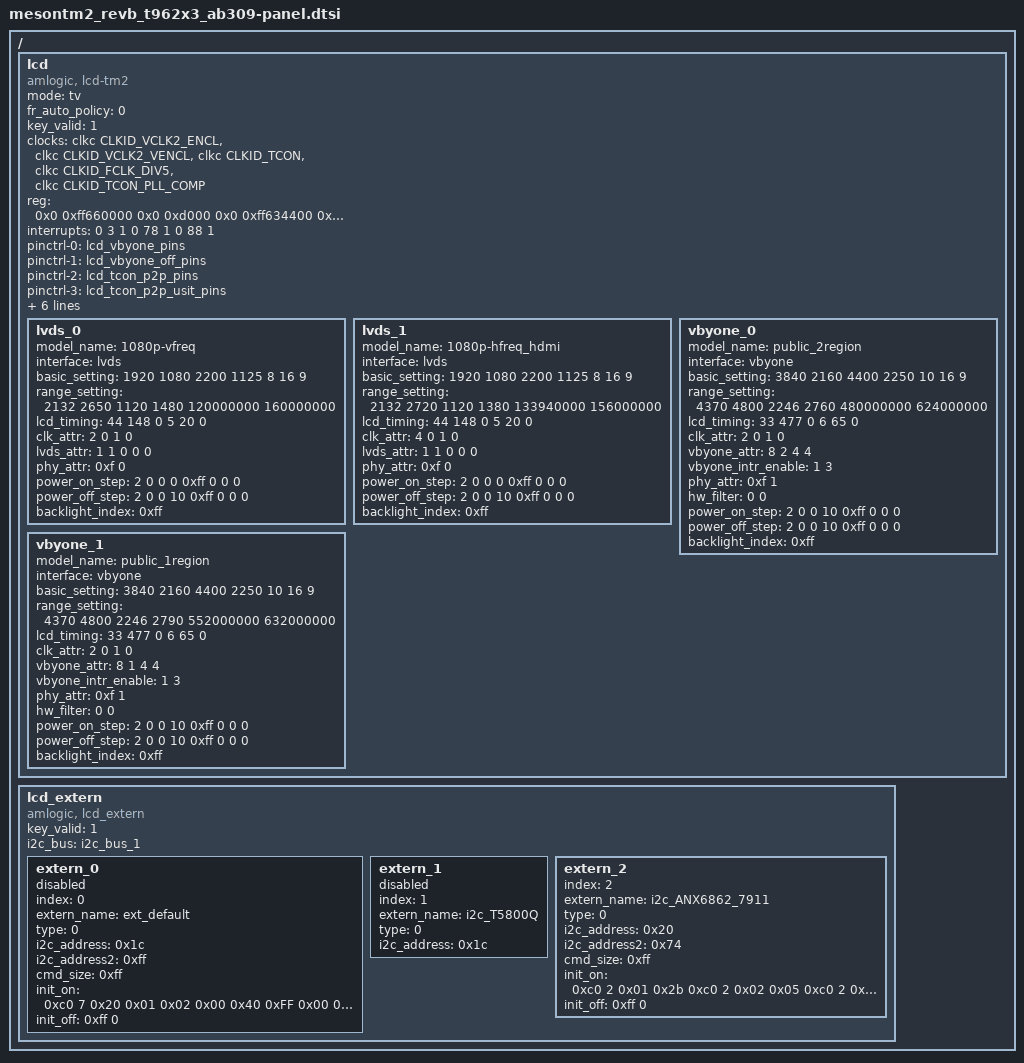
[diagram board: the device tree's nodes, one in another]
// SPDX-License-Identifier: (GPL-2.0+ OR MIT)
/*
 * arch/arm64/boot/dts/amlogic/mesontm2_revb_t962x3_ab309-panel.dtsi
 *
 * Copyright (C) 2019 Amlogic, Inc. All rights reserved.
 *
 */

/ {
	lcd {
		compatible = "amlogic, lcd-tm2";
		status = "okay";
		mode = "tv";
		fr_auto_policy = <0>; /* 0=disable, 1=60/50hz, 2=60/50/48hz */
		key_valid = <1>;
		clocks = <&clkc CLKID_VCLK2_ENCL
			&clkc CLKID_VCLK2_VENCL
			&clkc CLKID_TCON
			&clkc CLKID_FCLK_DIV5
			&clkc CLKID_TCON_PLL_COMP>;
		clock-names = "encl_top_gate",
			"encl_int_gate",
			"tcon_gate",
			"fclk_div5",
			"clk_tcon";
		reg = <0x0 0xff660000 0x0 0xd000
			0x0 0xff634400 0x0 0x300>;
		interrupts = <0 3 1
			0 78 1
			0 88 1>;
		interrupt-names = "vsync","vbyone","tcon";
		pinctrl-names = "vbyone","vbyone_off",
				"tcon_p2p","tcon_p2p_usit","tcon_p2p_off",
				"tcon_mlvds","tcon_mlvds_off";
		pinctrl-0 = <&lcd_vbyone_pins>;
		pinctrl-1 = <&lcd_vbyone_off_pins>;
		pinctrl-2 = <&lcd_tcon_p2p_pins>;
		pinctrl-3 = <&lcd_tcon_p2p_usit_pins>;
		pinctrl-4 = <&lcd_tcon_p2p_off_pins>;
		pinctrl-5 = <&lcd_tcon_mlvds_pins>;
		pinctrl-6 = <&lcd_tcon_mlvds_off_pins>;
		pinctrl_version = <2>; /* for uboot */

		/* power type:(0=cpu_gpio, 2=signal, 3=extern, 0xff=ending) */
		/* power index:(gpios_index, or extern_index, 0xff=invalid) */
		/* power value:(0=output low, 1=output high, 2=input) */
		/* power delay:(unit in ms) */

		config_check_glb = <1>;
		display_timing_req_min = <1  /*alert_level: 0:disable, 1:warning, 2:fatal error*/
			45   /*hsw+hbp*/
			0    /*hfp, 0 for no need*/
			20   /*vsw+vbp*/
			15>; /*vfp*/

		lvds_0{
			model_name = "1080p-vfreq";
			interface = "lvds"; /*lcd_interface(lvds, vbyone)*/
			basic_setting = <
				1920 1080 /*h_active, v_active*/
				2200 1125 /*h_period, v_period*/
				8      /*lcd_bits */
				16 9>; /*screen_widht, screen_height*/
			range_setting = <
				2132 2650  /*h_period_min,max*/
				1120 1480  /*v_period_min,max*/
				120000000 160000000>; /*pclk_min,max*/
			lcd_timing = <
				44 148 0  /*hs_width, hs_bp, hs_pol*/
				5  20 0>; /*vs_width, vs_bp, vs_pol*/
			clk_attr = <
				2 /*fr_adj_type: 0=clk, 1=htotal, 2=vtotal, 3=auto, 4=hdmi */
				0 /*clk_ss: [0:7]:level, [8:11]:freq, [12:15]: mode*/
				1 /*clk_auto_generate*/
				0>; /*pixel_clk(unit in Hz)*/
			lvds_attr = <
				1  /*lvds_repack*/
				1  /*dual_port*/
				0  /*pn_swap*/
				0  /*port_swap*/
				0>; /*lane_reverse*/
			phy_attr=<0xf 0>; /*vswing_level, preem_level*/

			/* power step: type, index, value, delay(ms) */
			power_on_step = <
				2 0 0 0   /*signal enable*/
				0xff 0 0 0>; /*ending*/
			power_off_step = <
				2 0 0 10  /*signal disable*/
				0xff 0 0 0>; /*ending*/
			backlight_index = <0xff>;
		};
		lvds_1{
			model_name = "1080p-hfreq_hdmi";
			interface = "lvds"; /*lcd_interface(lvds, vbyone)*/
			basic_setting = <
				1920 1080 /*h_active, v_active*/
				2200 1125 /*h_period, v_period*/
				8      /*lcd_bits*/
				16 9>; /*screen_widht, screen_height*/
			range_setting = <
				2132 2720 /*h_period min, max*/
				1120 1380 /*v_period min, max*/
				133940000 156000000>; /*pclk_min, max*/
			lcd_timing = <
				44 148 0   /*hs_width, hs_bp, hs_pol*/
				5  20  0>; /*vs_width, vs_bp, vs_pol*/
			clk_attr = <
				4 /*fr_adj_type: 0=clk, 1=htotal, 2=vtotal, 3=auto, 4=hdmi */
				0 /*clk_ss: [0:7]:level, [8:11]:freq, [12:15]: mode */
				1 /*clk_auto_generate*/
				0>; /*pixel_clk(unit in Hz)*/
			lvds_attr = <
				1 /*lvds_repack*/
				1 /*dual_port*/
				0 /*pn_swap*/
				0 /*port_swap*/
				0>; /*lane_reverse*/
			phy_attr=<0xf 0>; /*vswing_level, preem_level*/

			/* power step: type, index, value, delay(ms) */
			power_on_step = <
				2 0 0 0   /*signal enable*/
				0xff 0 0 0>; /*ending*/
			power_off_step = <
				2 0 0 10  /*signal disable*/
				0xff 0 0 0>; /*ending*/
			backlight_index = <0xff>;
		};
		vbyone_0{
			model_name = "public_2region";
			interface = "vbyone"; /*lcd_interface(lvds, vbyone)*/
			basic_setting = <
				3840 2160 /*h_active, v_active*/
				4400 2250 /*h_period, v_period*/
				10     /*lcd_bits */
				16 9>; /*screen_widht, screen_height*/
			range_setting = <
				4370 4800 /*h_period_min, max*/
				2246 2760 /*v_period_min, max*/
				480000000 624000000>; /*pclk_min, max*/
			lcd_timing = <
				33 477 0  /*hs_width, hs_bp, hs_pol*/
				6  65 0>; /*vs_width, vs_bp, vs_pol*/
			clk_attr = <
				2 /*fr_adj_type: 0=clk, 1=htotal, 2=vtotal, 3=auto, 4=hdmi */
				0 /*clk_ss: [0:7]:level, [8:11]:freq, [12:15]: mode*/
				1 /*clk_auto_generate*/
				0>; /*pixel_clk(unit in Hz)*/
			vbyone_attr = <
				8 /*lane_count*/
				2 /*region_num*/
				4 /*byte_mode*/
				4>; /*color_fmt*/
			vbyone_intr_enable = <
				1 /*vbyone_intr_enable */
				3>; /*vbyone_vsync_intr_enable*/
			phy_attr=<0xf 1>; /* vswing_level, preem_level */
			hw_filter=<0 0>;  /* filter_time, filter_cnt*/

			/* power step: type, index, value, delay(ms) */
			power_on_step = <
				2 0 0 10  /*signal enable*/
				0xff 0 0 0>; /*ending*/
			power_off_step = <
				2 0 0 10 /*signal disable*/
				0xff 0 0 0>; /*ending*/
			backlight_index = <0xff>;
		};
		vbyone_1{
			model_name = "public_1region";
			interface = "vbyone"; /*lcd_interface(lvds, vbyone)*/
			basic_setting = <
				3840 2160 /*h_active, v_active*/
				4400 2250 /*h_period, v_period*/
				10     /*lcd_bits*/
				16 9>; /*screen_widht, screen_height*/
			range_setting = <
				4370 4800 /*h_period_min, max*/
				2246 2790 /*v_period_min, max*/
				552000000 632000000>; /*pclk_min,max*/
			lcd_timing = <
				33 477 0   /*hs_width, hs_bp, hs_pol*/
				6  65  0>; /*vs_width, vs_bp, vs_pol*/
			clk_attr = <
				2 /*fr_adj_type: 0=clk, 1=htotal, 2=vtotal, 3=auto, 4=hdmi */
				0 /*clk_ss: [0:7]:level, [8:11]:freq, [12:15]: mode*/
				1 /*clk_auto_generate*/
				0>; /*pixel_clk(unit in Hz)*/
			vbyone_attr = <
				8 /*lane_count*/
				1 /*region_num*/
				4 /*byte_mode*/
				4>; /*color_fmt*/
			vbyone_intr_enable = <
				1   /*vbyone_intr_enable*/
				3>; /*vbyone_vsync_intr_enable*/
			phy_attr=<0xf 1>; /* vswing_level, preem_level */
			hw_filter=<0 0>;  /* filter_time, filter_cnt*/

			/* power step: type, index, value, delay(ms) */
			power_on_step = <
				2 0 0 10 /*signal enable*/
				0xff 0 0 0>; /*ending*/
			power_off_step = <
				2 0 0 10  /*signal disable*/
				0xff 0 0 0>; /*ending*/
			backlight_index = <0xff>;
		};
	};

	lcd_extern{
		compatible = "amlogic, lcd_extern";
		status = "okay";
		key_valid = <1>;
		i2c_bus = "i2c_bus_1";

		extern_0{
			index = <0>;
			extern_name = "ext_default";
			status = "disabled";
			type = <0>; /*0=i2c, 1=spi, 2=mipi*/
			i2c_address = <0x1c>; /*7bit i2c_addr*/
			i2c_address2 = <0xff>;
			cmd_size = <0xff>; /*dynamic cmd_size*/

			/* init on/off:
			 *  fixed cmd_size: (type, value...);
			 *                  cmd_size include all data.
			 *  dynamic cmd_size: (type, cmd_size, value...);
			 *                    cmd_size include value.
			 */
			/* type: 0x00=cmd with delay(bit[3:0]=1 for address2),
			 *       0xc0=cmd(bit[3:0]=1 for address2),
			 *       0xf0=gpio,
			 *       0xfd=delay,
			 *       0xff=ending
			 */
			/* value: i2c or spi cmd, or gpio index & level */
			/* delay: unit ms */
			init_on = <
				0xc0 7 0x20 0x01 0x02 0x00 0x40 0xFF 0x00
				0xc0 7 0x80 0x02 0x00 0x40 0x62 0x51 0x73
				0xc0 7 0x61 0x06 0x00 0x00 0x00 0x00 0x00
				0xc0 7 0xC1 0x05 0x0F 0x00 0x08 0x70 0x00
				0xc0 7 0x13 0x01 0x00 0x00 0x00 0x00 0x00
				0xc0 7 0x3D 0x02 0x01 0x00 0x00 0x00 0x00
				0xc0 7 0xED 0x0D 0x01 0x00 0x00 0x00 0x00
				0xc0 7 0x23 0x02 0x00 0x00 0x00 0x00 0x00
				0xfd 1 10 /* delay 10ms */
				0xff 0>; /*ending*/
			init_off = <0xff 0>; /*ending*/
		};
		extern_1{
			index = <1>;
			extern_name = "i2c_T5800Q";
			status = "disabled";
			type = <0>; /* 0=i2c, 1=spi, 2=mipi */
			i2c_address = <0x1c>; /* 7bit i2c address */
		};
		extern_2{
			index = <2>;
			extern_name = "i2c_ANX6862_7911";
			status = "okay";
			type = <0>; /* 0=i2c, 1=spi, 2=mipi */
			i2c_address = <0x20>; /* 7bit i2c address */
			i2c_address2 = <0x74>; /* 7bit i2c address */
			cmd_size = <0xff>;

			init_on = <
				0xc0 2 0x01 0x2b
				0xc0 2 0x02 0x05
				0xc0 2 0x03 0x00
				0xc0 2 0x04 0x00
				0xc0 2 0x05 0x0c
				0xc0 2 0x06 0x04
				0xc0 2 0x07 0x21
				0xc0 2 0x08 0x0f
				0xc0 2 0x09 0x04
				0xc0 2 0x0a 0x00
				0xc0 2 0x0b 0x04
				0xc0 2 0xff 0x00
				0xfd 1 100  /* delay 100ms */

				0xc1 2 0x01 0xca
				0xc1 2 0x02 0x3b
				0xc1 2 0x03 0x33
				0xc1 2 0x04 0x05
				0xc1 2 0x05 0x2c
				0xc1 2 0x06 0xf2
				0xc1 2 0x07 0x9c
				0xc1 2 0x08 0x1b
				0xc1 2 0x09 0x82
				0xc1 2 0x0a 0x3d
				0xc1 2 0x0b 0x20
				0xc1 2 0x0c 0x11
				0xc1 2 0x0d 0xc4
				0xc1 2 0x0e 0x1a
				0xc1 2 0x0f 0x31
				0xc1 2 0x10 0x4c
				0xc1 2 0x11 0x12
				0xc1 2 0x12 0x90
				0xc1 2 0x13 0xf7
				0xc1 2 0x14 0x0c
				0xc1 2 0x15 0x20
				0xc1 2 0x16 0x13
				0xff 0>; /*ending*/
			init_off = <0xff 0>; /*ending*/
		};
	};

}; /* end of / */
